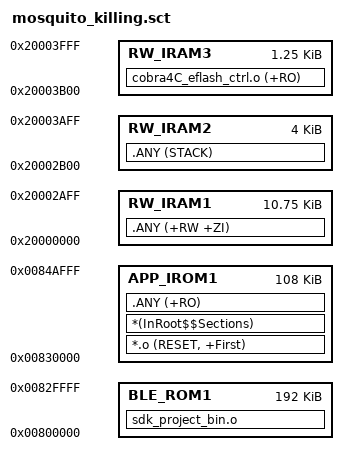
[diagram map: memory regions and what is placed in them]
#! armcc -E -I  .\  --cpu Cortex-M4

#include "cobra_config.h"

;#if 0	
;LR_IROM1 0x00800000 0x0004C000  {    ; load region size_region
  ;ER_IROM1 0x00800000 0x0004C000   {  ; load address = execution address
   ;*.o (RESET, +First)
   ;*(InRoot$$Sections)
   ;.ANY (+RO)
  ;}
  
  ;;RW_IRAM1 0x20000000 0x0000b800  {  ; RW data
   ;;.ANY (+RW +ZI)
  ;;}

  ;RW_IRAM1 0x20000000 0x0000b200  {  ; RW data
   ;.ANY (+RW +ZI)
  ;}   
  ;;RW_IRAM2 0x2000b200 UNINIT 0x000000100  {  ; RW data
   ;;.ANY (retention_area)              ; zero initialized SDK + application data
  ;;}  
  ;RW_IRAM3 0x2000b300 0x00000500  {  ; RW data
   ;cobra4C_eflash_ctrl.o (+RO)
  ;}
;}
;#else
;APP firmware
APP_IROM1 0x00830000 (0x4B000-0x30000)
{    ; load region size_region
   APP_IROM1 0x00830000 (0x4B000-0x30000)
   {  ; load address = execution address
      *.o (RESET, +First)
      *(InRoot$$Sections)
      .ANY (+RO)
   }

   RW_IRAM1 0x20000000 0x00002B00  
   {  ; RW data
       .ANY (+RW +ZI)
   }
   
   RW_IRAM2 0x20002B00 0x00001000  
   {  ; RW data
       .ANY (STACK)
   }
   
  RW_IRAM3 0x20003B00 0x00000500  {  ; RW data
   cobra4C_eflash_ctrl.o (+RO)
  }   
}

;ble protocol
BLE_ROM1 0x00800000 0x0030000
{
    BLE_ROM1  0x00800000 0x0030000
	{
       sdk_project_bin.o
    }
}
;#endif



